# GD32M53x register map
File version: 1.0
CPU: CM33 r2p1, little endian, MPU, FPU, DSP, 4 interrupt priority bits
Registers are 32-bit, read-write, reset 0x0 unless marked. A register's access mark holds for its fields unless they carry their own. Offsets are from the block's base; [hi:lo] are bit positions.

## SPI — Serial peripheral interface
Base 0x40013000
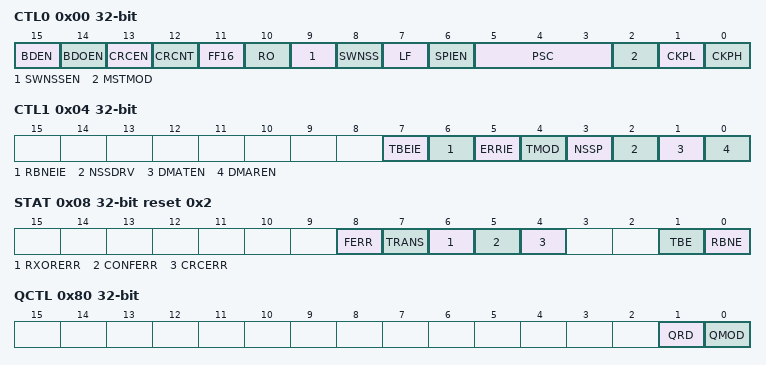
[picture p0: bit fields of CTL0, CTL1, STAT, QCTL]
0x00 CTL0 — control register 0
  [15] BDEN — Bidirectional enable
  [14] BDOEN — Bidirectional Transmit output enable
  [13] CRCEN — CRC Calculation Enable
  [12] CRCNT — CRC Next Transfer
  [11] FF16 — Data frame format
  [10] RO — Receive only
  [9] SWNSSEN — NSS Software Mode Selection
  [8] SWNSS — NSS Pin Selection In NSS Software Mode
  [7] LF — LSB First Mode
  [6] SPIEN — SPI enable
  [5:3] PSC — Master Clock Prescaler Selection
  [2] MSTMOD — Master Mode Enable
  [1] CKPL — Clock polarity Selection
  [0] CKPH — Clock Phase Selection
0x04 CTL1 — control register 1
  [7] TBEIE — Tx buffer empty interrupt enable
  [6] RBNEIE — RX buffer not empty interrupt enable
  [5] ERRIE — Error interrupt enable
  [4] TMOD — SPI TI Mode Enable
  [3] NSSP — SPI NSS pulse mode Enable
  [2] NSSDRV — Drive NSS Output
  [1] DMATEN — Transmit Buffer DMA Enable
  [0] DMAREN — Rx buffer DMA enable
0x08 STAT access per field reset 0x2 — status register
  [8] FERR rw — Format Error
  [7] TRANS ro — Transmitting On-going Bit
  [6] RXORERR ro — Reception Overrun Error Bit
  [5] CONFERR ro — SPI Configuration error
  [4] CRCERR rw — SPI CRC Error Bit
  [1] TBE ro — Transmit Buffer Empty
  [0] RBNE ro — Receive Buffer Not Empty
0x0C DATA
  [15:0] SPI_DATA — Data transfer register
0x10 CRCPOLY reset 0x7 — CRC polynomial register
  [15:0] CRCPOLY
0x14 RCRC ro — RX CRC register
  [15:0] RCRC
0x18 TCRC ro — TX CRC register
  [15:0] TCRC — Tx CRC register
0x80 QCTL — Quad-SPI mode control register
  [1] QRD — Quad-SPI mode read select
  [0] QMOD — Quad-SPI mode enable

## SVPWM — Space Vector Pulse Width Modulation
Base 0x48024000
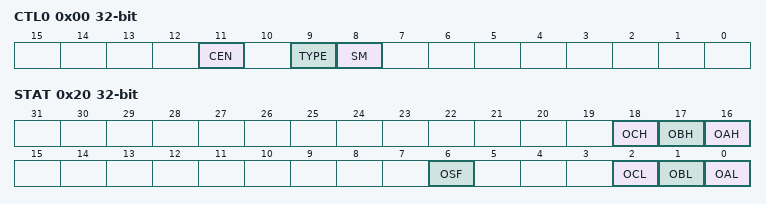
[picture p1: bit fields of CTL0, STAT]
0x00 CTL0 — Control register 0
  [11] CEN — SVPWM peripheral enable
  [9] TYPE — Five-segment SVPWM and Seven-segment SVPWM select flag bit
  [8] SM — Switch mode
0x04 UALPHA reset 0x3F800000
  [31:0] UALPHA — This data represents the UALPHA input to the SVPWM module
0x08 UBETA reset 0x3F800000
  [31:0] UBETA — This data represents the UBETA input to the SVPWM module
0x0C CAR — Counter auto reload register
  [15:0] CAR — This bit-field indicates the period of TIMER
0x10 TA ro
  [15:0] TA — This data represents the TA output to the SVPWM module
0x14 TB ro
  [15:0] TB — This data represents the TB output to the SVPWM module
0x18 TC ro
  [15:0] TC — This data represents the TC output to the SVPWM module
0x1C SEC ro — Sector register
  [2:0] SEC — Sector value to the SVPWM module
0x20 STAT ro — Status register
  [18] OCH — The duty cycle of C-phase is greater than the COUNT overflow flag
  [17] OBH — The duty cycle of B-phase is greater than the COUNT overflow flag
  [16] OAH — The duty cycle of A-phase is greater than the COUNT overflow flag
  [6] OSF — SVPWM operation status flag bit
  [2] OCL — The duty cycle of C-phase is less than 0 overflow flag
  [1] OBL — The duty cycle of B-phase is less than 0 overflow flag
  [0] OAL — The duty cycle of A-phase is less than 0 overflow flag

## TMU — Trigonometric Math Unit
Base 0x48024400
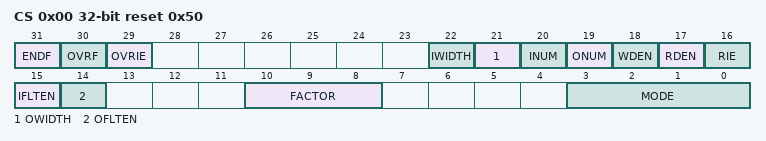
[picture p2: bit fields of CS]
0x00 CS access per field reset 0x50 — Control and status register
  [31] ENDF ro — End of TMU operation flag
  [30] OVRF ro — The flag of overflow
  [29] OVRIE rw — Overflow interrupt enable
  [22] IWIDTH rw — Width of input data
  [21] OWIDTH rw — Width of output data
  [20] INUM rw — The number of times that the TMU_IDATA needs to be written
  [19] ONUM rw — The number of times that the TMU_ODATA needs to be read
  [18] WDEN rw — Enable DMA request to write TMU_IDATA
  [17] RDEN rw — Enable DMA request to read TMU_ODATA
  [16] RIE rw — Enable interrupt request to read TMU_ODATA
  [15] IFLTEN rw — Input Floating Point Format Enable
  [14] OFLTEN rw — Output Floating Point Format Enable
  [10:8] FACTOR rw — Scaling factor
  [3:0] MODE rw — Mode of TMU operation
0x04 IDATA wo — Input data register
  [31:0] IDATA — The input data
0x08 ODATA ro — Output Data register
  [31:0] ODATA — The output data

## UART0 — Universal synchronous asynchronous receiver transmitter
Base 0x40004C00
Same registers: UART1 0x40005000, UART2 0x40007800, UART3 0x40007C00
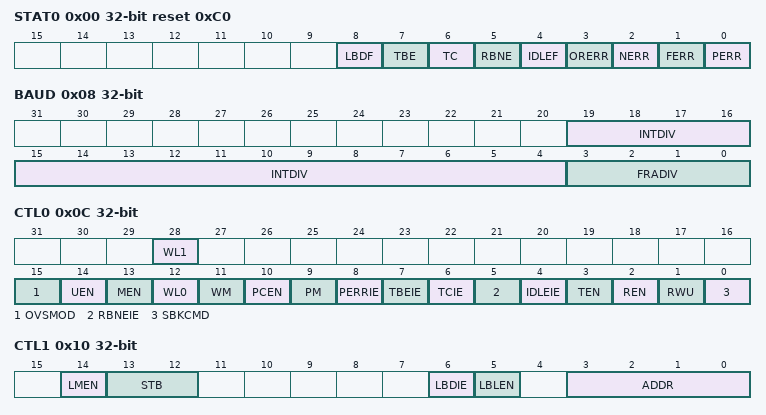
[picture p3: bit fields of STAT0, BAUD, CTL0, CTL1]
0x00 STAT0 access per field reset 0xC0 — Status register 0
  [8] LBDF rw — LIN break detection flag
  [7] TBE ro — Transmit data buffer empty
  [6] TC rw — Transmission complete
  [5] RBNE rw — Read data buffer not empty
  [4] IDLEF ro — IDLE frame detected flag
  [3] ORERR ro — Overrun error
  [2] NERR ro — Noise error flag
  [1] FERR ro — Frame error flag
  [0] PERR ro — Parity error flag
0x04 DATA
  [9:0] DATA — Transmit or read data value
0x08 BAUD — Baud rate register
  [19:4] INTDIV — Integer part of baud-rate divider
  [3:0] FRADIV — Fraction part of baud-rate divider
0x0C CTL0 — Control register 0
  [28] WL1 — Word length
  [15] OVSMOD — Oversample mode
  [14] UEN — USART enable
  [13] MEN — Mute mode enable
  [12] WL0 — Word length
  [11] WM — Wakeup method in mute mode
  [10] PCEN — Parity check function enable
  [9] PM — Parity mode
  [8] PERRIE — Parity error interrupt enable
  [7] TBEIE — Transmitter buffer empty interrupt enable
  [6] TCIE — Transmission complete interrupt enable
  [5] RBNEIE — Read data buffer not empty interrupt and overrun error interrupt enable
  [4] IDLEIE — IDLE line detected interrupt enable
  [3] TEN — Transmitter enable
  [2] REN — Receiver enable
  [1] RWU — Receiver wakeup from mute mode
  [0] SBKCMD — Send break command
0x10 CTL1 — Control register 1
  [14] LMEN — LIN mode enable
  [13:12] STB — STOP bits length
  [6] LBDIE — LIN break detection interrupt enable
  [5] LBLEN — LIN break frame length
  [3:0] ADDR — Address of the USART
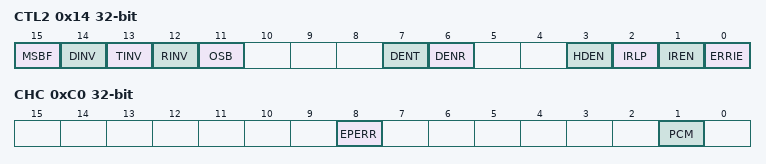
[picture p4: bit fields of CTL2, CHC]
0x14 CTL2 — Control register 2
  [15] MSBF — Most significant bit first
  [14] DINV — Data bit level inversion
  [13] TINV — TX pin level inversion
  [12] RINV — RX pin level inversion
  [11] OSB — One sample bit method
  [7] DENT — DMA request enable for transmission
  [6] DENR — DMA request enable for reception
  [3] HDEN — Half-duplex selection
  [2] IRLP — IrDA low-power
  [1] IREN — IrDA mode enable
  [0] ERRIE — Error interrupt enable
0x18 GP — Guard time and prescaler register
  [7:0] PSC — Prescaler value
0xC0 CHC access per field — Coherence control register
  [8] EPERR wo — Early parity error flag
  [1] PCM rw — Parity check coherence mode

## WWDGT — Window watchdog timer
Base 0x40002C00
0x00 CTL reset 0x3FFF — Control register
  [13:0] CNT — 14-bit counter
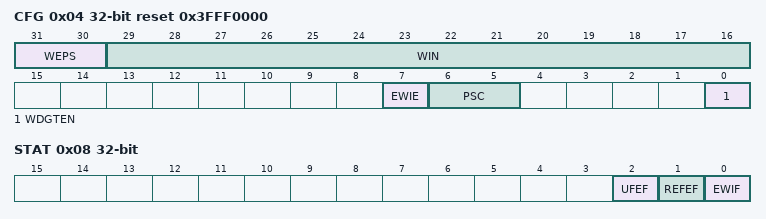
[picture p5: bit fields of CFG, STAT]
0x04 CFG reset 0x3FFF0000 — Configuration register
  [31:30] WEPS — Window end position selection
  [29:16] WIN — 14-bit window value
  [7] EWIE — Early wakeup interrupt
  [6:5] PSC — Prescaler
  [0] WDGTEN — Activation bit
0x08 STAT — Status register
  [2] UFEF — Underflow error flag
  [1] REFEF — Refresh error flag
  [0] EWIF — Early wakeup interrupt flag
